# PY32T020xx register map
Vendor: Puya; Series: PY32L0; File version: 1.0.0
CPU: CM0+ r0p1, little endian, no MPU, no FPU, 4 interrupt priority bits
Registers are 32-bit, read-write, reset 0x0 unless marked. A register's access mark holds for its fields unless they carry their own. Offsets are from the block's base; [hi:lo] are bit positions.

## RCC — Reset and clock control
Base 0x40021000
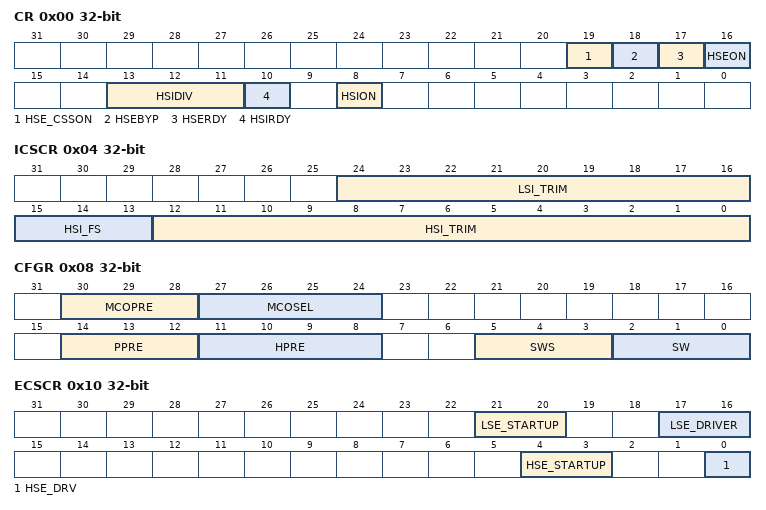
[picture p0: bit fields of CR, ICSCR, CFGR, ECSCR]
0x00 CR — Clock control register
  [19] HSE_CSSON — HSE clock security system enabled
  [18] HSEBYP — HSE shields the crystal oscillator and selects the pin input clock
  [17] HSERDY ro — HSE crystal clock ready flag
  [16] HSEON — HSE crystal oscillator enabled
  [13:11] HSIDIV — HSI generates the crossover factor when HSISYS clocks
    1=0; 2=1; 4=2
  [10] HSIRDY ro — HSI clock ready logo
  [8] HSION — HSI clock enable bit
0x04 ICSCR — Internal clock sources calibration register
  [24:16] LSI_TRIM — Internal low-speed clock frequency calibration
    1=0; 2=1; 4=2; 8=3; 16=4; 32=5; 64=6; 128=7; 0x100=8
  [15:13] HSI_FS — HSI frequency selection
    4=Freq24MHz (24 MHz HSI clock)
  [12:0] HSI_TRIM — Clock frequency calibration value
    1=0; 2=1; 4=2; 8=3; 16=4; 32=5; 64=6; 128=7; 0x100=8; 0x200=9; 0x400=10; 0x800=11; 0x1000=12
0x08 CFGR — Clock configuration register
  [30:28] MCOPRE — Microprocessor output clock (MCO) divider factor
    1=0; 2=1; 4=2
  [27:24] MCOSEL — MCO output clock selection
    1=0; 2=1; 4=2; 8=MCO Prescaler configuration
  [14:12] PPRE — APB clock division factor
    1=0; 2=1; 4=2
  [11:8] HPRE — The AHB clock HCLK is based on the crossover coefficient of SYSCLK
    1=0; 2=1; 4=2; 8=3
  [5:3] SWS — System clock source selection
    0=HSISYS (HSISYS used as system clock); 1=0; 1=HSE (HSE used as system clock); 2=1; 3=LSI (LSI used as system clock); 4=2; 4=LSE (LSE used as system clock)
  [2:0] SW — System clock source selection
    1=0; 2=1; 4=2
0x10 ECSCR — External clock source control register
  [21:20] LSE_STARTUP — LSE crystal oscillator stabilization time selection
    1=0; 2=1
  [17:16] LSE_DRIVER — LSE drive capability setting
    1=0; 2=1
  [4:3] HSE_STARTUP — HSE stabilization time selection
    1=0; 2=1
  [0] HSE_DRV — HSE drive capability setting
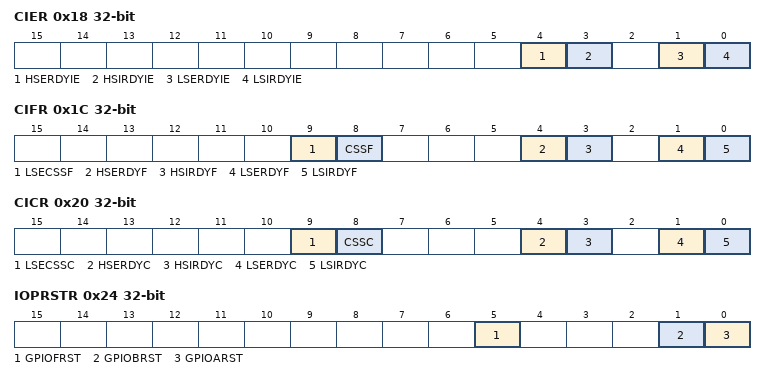
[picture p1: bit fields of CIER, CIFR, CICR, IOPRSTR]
0x18 CIER — Clock interrupt enable register
  [4] HSERDYIE — HSE clock ready interrupt enabled
  [3] HSIRDYIE — HSI clock ready interrupt enabled
  [1] LSERDYIE — LSE clock ready interrupt enabled
  [0] LSIRDYIE — LSI clock ready interrupt enabled
0x1C CIFR — Clock interrupt flag register
  [9] LSECSSF ro — LSE Clock Security System (CSS) interrupt flag
  [8] CSSF ro — HSE Clock Security System (CSS) interrupt flag
  [4] HSERDYF ro — HSE clock ready interrupt enabled
  [3] HSIRDYF ro — HSI clock ready interrupt enabled
  [1] LSERDYF ro — LSE clock ready interrupt enabled
  [0] LSIRDYF ro — LSI clock ready interrupt enabled
0x20 CICR — Clock interrupt clear register
  [9] LSECSSC wo — The LSE Clock Security System (CSS) interrupt flag is cleared
  [8] CSSC wo — The HSE Clock Security System (CSS) interrupt flag is cleared to zero
  [4] HSERDYC wo — The HSE ready interrupt flag is cleared to zero
  [3] HSIRDYC wo — The HSI ready interrupt flag is cleared to zero
  [1] LSERDYC wo — The LSE ready interrupt flag is cleared
  [0] LSIRDYC wo — The LSI ready interrupt flag is cleared
0x24 IOPRSTR — GPIO reset register
  [5] GPIOFRST — I/O PortF reset
  [1] GPIOBRST — I/O PortB reset
  [0] GPIOARST — I/O PortA reset
0x28 AHBRSTR — AHB peripheral reset register
  [12] CRCRST — The CRC module is reset
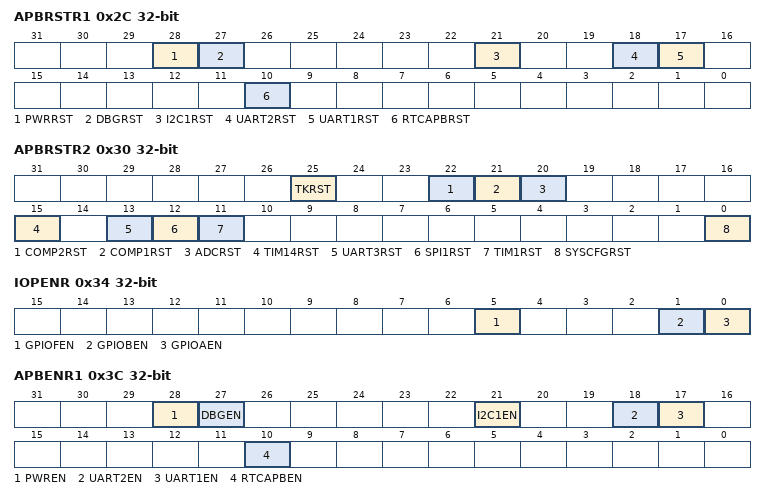
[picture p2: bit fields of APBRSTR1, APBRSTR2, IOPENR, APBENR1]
0x2C APBRSTR1 — APB peripheral reset register 1
  [28] PWRRST — The Power interface module is reset.
  [27] DBGRST — The MCU Debug module is reset
  [21] I2C1RST — The I2C1 module is reset
  [18] UART2RST — The UART2 module is reset
  [17] UART1RST — The UART1 module is reset
  [10] RTCAPBRST — The RTC module APB is reset
0x30 APBRSTR2 — APB peripheral reset register 2
  [25] TKRST — TK module reset
  [22] COMP2RST — The COMP2 module is reset
  [21] COMP1RST — The COMP1 module is reset
  [20] ADCRST — The ADC block is reset
  [15] TIM14RST — The TIM14 module is reset
  [13] UART3RST — The UART3 module is reset
  [12] SPI1RST — The SPI1 module is reset
  [11] TIM1RST — The TIM1 module is reset
  [0] SYSCFGRST — The SYSCFG module is reset
0x34 IOPENR — GPIO clock enable register
  [5] GPIOFEN — I/O PortF clock enable
  [1] GPIOBEN — I/O PortB clock enable
  [0] GPIOAEN — I/O PortA clock enable
0x38 AHBENR — AHB peripheral clock enable register
  [12] CRCEN — CRC module clock enabled
0x3C APBENR1 — APB peripheral clock enable register 1
  [28] PWREN — The Power interface module clock enables
  [27] DBGEN — MCU Debug module clock enable
  [21] I2C1EN — I2C1 module clock enable
  [18] UART2EN — The UART2 module clock is enabled
  [17] UART1EN — The UART1 module clock is enabled
  [10] RTCAPBEN — The RTC module APB clock is enabled
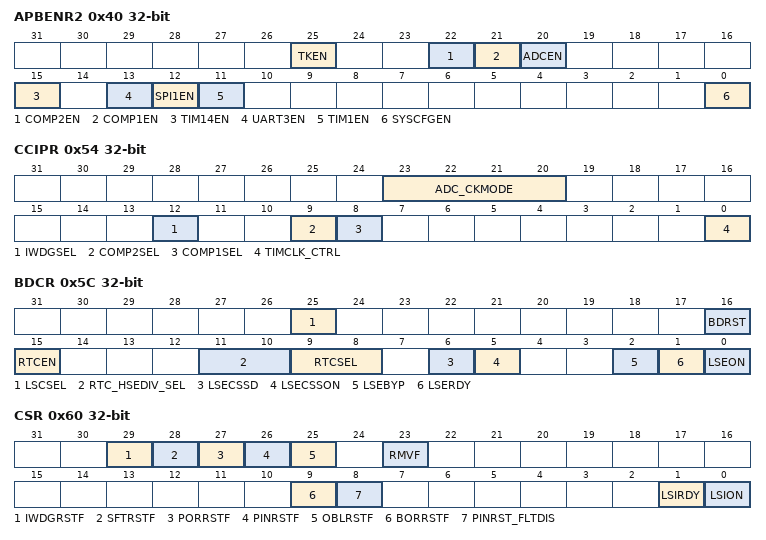
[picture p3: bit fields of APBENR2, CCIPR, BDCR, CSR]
0x40 APBENR2 — APB peripheral clock enable register 2
  [25] TKEN — TK module clock enabled
  [22] COMP2EN — COMP2 module clock enabled
  [21] COMP1EN — COMP1 module clock enable
  [20] ADCEN — ADC block clock enabled
  [15] TIM14EN — TIM14 module clock enable
  [13] UART3EN — The UART3 module clock is enabled
  [12] SPI1EN — The SPI1 module clock is enabled
  [11] TIM1EN — The TIM1 module clock is enabled
  [0] SYSCFGEN — The SYSCFG module clock is enabled
0x54 CCIPR — Peripherals independent clock configuration register
  [23:20] ADC_CKMODE — ADC clock mode
    1=0; 2=1; 4=2; 8=3
  [12] IWDGSEL — IWDG internal clock source selection
  [9] COMP2SEL — COMP2 module clock source selection
  [8] COMP1SEL — COMP1 module clock source selection
  [0] TIMCLK_CTRL — TIMER PCLK FREQUENCY CONTROL
0x5C BDCR — RTC domain control register
  [25] LSCSEL — Low-speed clock selection
  [16] BDRST — RTC soft reset
  [15] RTCEN — RTC clock enabled
  [11:10] RTC_HSEDIV_SEL — The RTC clock source is selected as the division of the HSE clock
    1=0; 2=1
  [9:8] RTCSEL — RTC clock source selection
    1=0; 2=1
  [6] LSECSSD — LSE CSS (clock security system) detection failed
  [5] LSECSSON — LSE CSS enables
  [2] LSEBYP — LSE OSC bypass
  [1] LSERDY — LSE OSC ready
  [0] LSEON — LSE OSC enabled
0x60 CSR — Control/status register
  [29] IWDGRSTF ro — IWDG reset flag
  [28] SFTRSTF ro — Soft reset flag
  [27] PORRSTF ro — POR reset flag
  [26] PINRSTF ro — External NRST pin reset flag
  [25] OBLRSTF ro — Option byte loader reset flag
  [23] RMVF — Clear the reset flag
  [9] BORRSTF ro — BOR reset flag
  [8] PINRST_FLTDIS — NRST filtering is prohibited
  [1] LSIRDY ro — LSI OSC stability flag
  [0] LSION — LSI OSC enabled
